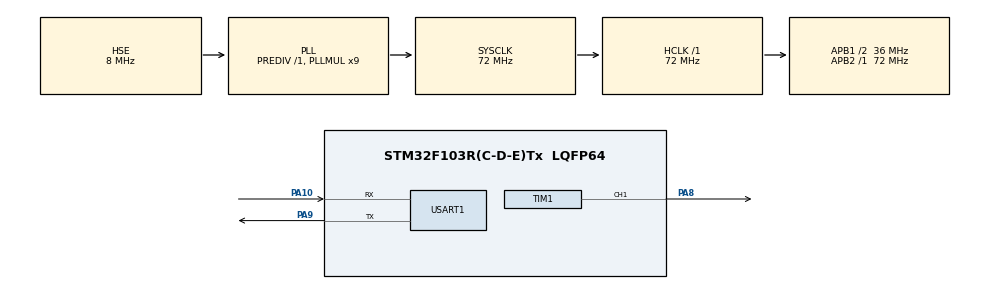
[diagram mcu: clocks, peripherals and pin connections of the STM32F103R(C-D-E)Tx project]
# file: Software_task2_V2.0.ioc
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Dma.Request0=USART1_RX
Dma.Request1=USART1_TX
Dma.USART1_RX.0.Direction=DMA_PERIPH_TO_MEMORY
Dma.USART1_RX.0.Instance=DMA1_Channel5
Dma.USART1_RX.0.MemDataAlignment=DMA_MDATAALIGN_BYTE
Dma.USART1_RX.0.MemInc=DMA_MINC_ENABLE
Dma.USART1_RX.0.Mode=DMA_NORMAL
Dma.USART1_RX.0.PeriphDataAlignment=DMA_PDATAALIGN_BYTE
Dma.USART1_RX.0.PeriphInc=DMA_PINC_DISABLE
Dma.USART1_RX.0.Priority=DMA_PRIORITY_LOW
Dma.USART1_TX.1.Direction=DMA_MEMORY_TO_PERIPH
Dma.USART1_TX.1.Instance=DMA1_Channel4
Dma.USART1_TX.1.MemDataAlignment=DMA_MDATAALIGN_BYTE
Dma.USART1_TX.1.MemInc=DMA_MINC_ENABLE
Dma.USART1_TX.1.Mode=DMA_NORMAL
Dma.USART1_TX.1.PeriphDataAlignment=DMA_PDATAALIGN_BYTE
Dma.USART1_TX.1.PeriphInc=DMA_PINC_DISABLE
Dma.USART1_TX.1.Priority=DMA_PRIORITY_LOW
FREERTOS.Queues01=Uart_Queue,1,uint16_t,0,Dynamic,NULL,NULL
FREERTOS.Tasks01=defaultTask,24,128,StartDefaultTask,Default,NULL,Dynamic,NULL,NULL;LED_Breath,9,128,LED_BreathTask,Default,NULL,Dynamic,NULL,NULL;Uart_Receive,10,128,Uart_ReceiveTask,Default,NULL,Dynamic,NULL,NULL
Mcu.Family=STM32F1
Mcu.Name=STM32F103R(C-D-E)Tx
Mcu.Package=LQFP64
NVIC.DMA1_Channel4_IRQn=true\:0\:0\:false\:false\:true\:false\:false\:true\:true
NVIC.DMA1_Channel5_IRQn=true\:0\:0\:false\:false\:true\:false\:false\:true\:true
NVIC.PriorityGroup=NVIC_PRIORITYGROUP_4
NVIC.TIM1_BRK_IRQn=true\:5\:0\:false\:false\:true\:true\:true\:true\:true
NVIC.TIM1_UP_IRQn=true\:5\:0\:false\:false\:true\:true\:true\:true\:true
NVIC.TIM6_IRQn=true\:15\:0\:false\:false\:true\:false\:false\:true\:true
NVIC.TimeBase=TIM6_IRQn
NVIC.TimeBaseIP=TIM6
NVIC.USART1_IRQn=true\:5\:0\:false\:false\:true\:true\:true\:true\:true
PA10.Mode=Asynchronous
PA10.Signal=USART1_RX
PA8.Signal=S_TIM1_CH1
PA9.Mode=Asynchronous
PA9.Signal=USART1_TX
PD0-OSC_IN.Mode=HSE-External-Oscillator
PD0-OSC_IN.Signal=RCC_OSC_IN
PD1-OSC_OUT.Mode=HSE-External-Oscillator
PD1-OSC_OUT.Signal=RCC_OSC_OUT
ProjectManager.HeapSize=0x200
ProjectManager.StackSize=0x400
ProjectManager.TargetToolchain=MDK-ARM V5.32
RCC.AHBFreq_Value=72000000
RCC.APB1CLKDivider=RCC_HCLK_DIV2
RCC.APB1Freq_Value=36000000
RCC.APB1TimFreq_Value=72000000
RCC.APB2Freq_Value=72000000
RCC.APB2TimFreq_Value=72000000
RCC.HCLKFreq_Value=72000000
RCC.PLLMUL=RCC_PLL_MUL9
RCC.PLLSourceVirtual=RCC_PLLSOURCE_HSE
RCC.SYSCLKFreq_VALUE=72000000
RCC.SYSCLKSource=RCC_SYSCLKSOURCE_PLLCLK
RCC.USBFreq_Value=72000000
SH.S_TIM1_CH1.0=TIM1_CH1,PWM Generation1 CH1
TIM1.Channel-PWM\ Generation1\ CH1=TIM_CHANNEL_1
TIM1.OCPolarity_1=TIM_OCPOLARITY_LOW
TIM1.Period=499
TIM1.Prescaler=71
USART1.VirtualMode=VM_ASYNC
VP_FREERTOS_VS_CMSIS_V2.Mode=CMSIS_V2
VP_SYS_VS_ND.Mode=No_Debug
VP_SYS_VS_tim6.Mode=TIM6
VP_TIM1_VS_ClockSourceINT.Mode=Internal
board=custom

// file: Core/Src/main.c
/* USER CODE BEGIN Header */
/**
  ******************************************************************************
  * @file           : main.c
  * @brief          : Main program body
  ******************************************************************************
  * @attention
  *
  * Copyright (c) 2023 STMicroelectronics.
  * All rights reserved.
  *
  * This software is licensed under terms that can be found in the LICENSE file
  * in the root directory of this software component.
  * If no LICENSE file comes with this software, it is provided AS-IS.
  *
  ******************************************************************************
  */
/* USER CODE END Header */
#include "main.h"
#include "cmsis_os.h"
#include "dma.h"
#include "tim.h"
#include "usart.h"
#include "gpio.h"

/* USER CODE BEGIN PD */
#define BUFFSIZE	50
char rxBUFF[BUFFSIZE]={0};
/* USER CODE END PD */

/* USER CODE BEGIN PV */
	int pwmval=0;	//PWMռ�ձ�
	int task1_flag=0;
	int task2_flag=0;
	int IRQ_flag=0;
	int Callback_flag=0;
/* USER CODE END PV */

void SystemClock_Config(void);
void MX_FREERTOS_Init(void);

int main(void)
{

  /* MCU Configuration--------------------------------------------------------*/

  /* Reset of all peripherals, Initializes the Flash interface and the Systick. */
  HAL_Init();

  /* Configure the system clock */
  SystemClock_Config();

  /* Initialize all configured peripherals */
  MX_GPIO_Init();
  MX_DMA_Init();
  MX_USART1_UART_Init();
  MX_TIM1_Init();
  /* USER CODE BEGIN 2 */
	HAL_TIM_PWM_Start(&htim1,TIM_CHANNEL_1);
//	HAL_UART_Receive_DMA(&huart1,(u8 *)rxBUFF,BUFFSIZE);
	HAL_UART_Receive_IT(&huart1, (u8 *)rxBUFF,BUFFSIZE);
  /* USER CODE END 2 */

  /* Init scheduler */
  osKernelInitialize();  /* Call init function for freertos objects (in freertos.c) */
  MX_FREERTOS_Init();

  /* Start scheduler */
  osKernelStart();
  /* We should never get here as control is now taken by the scheduler */
  /* Infinite loop */
  while (1)
  {

  }
}

void SystemClock_Config(void)
{
  RCC_OscInitTypeDef RCC_OscInitStruct = {0};
  RCC_ClkInitTypeDef RCC_ClkInitStruct = {0};

  /** Initializes the RCC Oscillators according to the specified parameters
  * in the RCC_OscInitTypeDef structure.
  */
  RCC_OscInitStruct.OscillatorType = RCC_OSCILLATORTYPE_HSE;
  RCC_OscInitStruct.HSEState = RCC_HSE_ON;
  RCC_OscInitStruct.HSEPredivValue = RCC_HSE_PREDIV_DIV1;
  RCC_OscInitStruct.HSIState = RCC_HSI_ON;
  RCC_OscInitStruct.PLL.PLLState = RCC_PLL_ON;
  RCC_OscInitStruct.PLL.PLLSource = RCC_PLLSOURCE_HSE;
  RCC_OscInitStruct.PLL.PLLMUL = RCC_PLL_MUL9;
  if (HAL_RCC_OscConfig(&RCC_OscInitStruct) != HAL_OK)
  {
    Error_Handler();
  }

  /** Initializes the CPU, AHB and APB buses clocks
  */
  RCC_ClkInitStruct.ClockType = RCC_CLOCKTYPE_HCLK|RCC_CLOCKTYPE_SYSCLK
                              |RCC_CLOCKTYPE_PCLK1|RCC_CLOCKTYPE_PCLK2;
  RCC_ClkInitStruct.SYSCLKSource = RCC_SYSCLKSOURCE_PLLCLK;
  RCC_ClkInitStruct.AHBCLKDivider = RCC_SYSCLK_DIV1;
  RCC_ClkInitStruct.APB1CLKDivider = RCC_HCLK_DIV2;
  RCC_ClkInitStruct.APB2CLKDivider = RCC_HCLK_DIV1;

  if (HAL_RCC_ClockConfig(&RCC_ClkInitStruct, FLASH_LATENCY_2) != HAL_OK)
  {
    Error_Handler();
  }
}

void HAL_TIM_PeriodElapsedCallback(TIM_HandleTypeDef *htim)
{
  if (htim->Instance == TIM6) {
    HAL_IncTick();
  }
}

void Error_Handler(void)
{
  __disable_irq();
  while (1)
  {
  }
}

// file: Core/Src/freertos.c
/* USER CODE BEGIN Header */
/**
  ******************************************************************************
  * File Name          : freertos.c
  * Description        : Code for freertos applications
  ******************************************************************************
  * @attention
  *
  * Copyright (c) 2023 STMicroelectronics.
  * All rights reserved.
  *
  * This software is licensed under terms that can be found in the LICENSE file
  * in the root directory of this software component.
  * If no LICENSE file comes with this software, it is provided AS-IS.
  *
  ******************************************************************************
  */
/* USER CODE END Header */

#include "FreeRTOS.h"
#include "task.h"
#include "main.h"
#include "cmsis_os.h"

/* USER CODE BEGIN Includes */
#include "tim.h"
#include "queue.h"
#include "usart.h"
#include "stdio.h"
/* USER CODE END Includes */

/* USER CODE BEGIN Variables */
	extern int pwmval;
	extern int task1_flag;
	extern int task2_flag;
	extern int IRQ_flag;
	extern int Callback_flag;
	extern char rxBUFF[];
	uint32_t rx_counter = 0;
	int rx_complete = 0;
/* USER CODE END Variables */
/* Definitions for defaultTask */
osThreadId_t defaultTaskHandle;
const osThreadAttr_t defaultTask_attributes = {
  .name = "defaultTask",
  .stack_size = 128 * 4,
  .priority = (osPriority_t) osPriorityNormal,
};
/* Definitions for LED_Breath */
osThreadId_t LED_BreathHandle;
const osThreadAttr_t LED_Breath_attributes = {
  .name = "LED_Breath",
  .stack_size = 128 * 4,
  .priority = (osPriority_t) osPriorityLow1,
};
/* Definitions for Uart_Receive */
osThreadId_t Uart_ReceiveHandle;
const osThreadAttr_t Uart_Receive_attributes = {
  .name = "Uart_Receive",
  .stack_size = 128 * 4,
  .priority = (osPriority_t) osPriorityLow2,
};
/* Definitions for Uart_Queue */
osMessageQueueId_t Uart_QueueHandle;
const osMessageQueueAttr_t Uart_Queue_attributes = {
  .name = "Uart_Queue"
};

/* USER CODE BEGIN FunctionPrototypes */
void DMA_TransferCompleteCallback(DMA_HandleTypeDef *hdma);
/* USER CODE END FunctionPrototypes */

void StartDefaultTask(void *argument);
void LED_BreathTask(void *argument);
void Uart_ReceiveTask(void *argument);

void MX_FREERTOS_Init(void); /* (MISRA C 2004 rule 8.1) */

void MX_FREERTOS_Init(void) {
  /* USER CODE BEGIN Init */
	HAL_DMA_RegisterCallback(&hdma_usart1_rx, HAL_DMA_XFER_CPLT_CB_ID, DMA_TransferCompleteCallback);
  /* USER CODE END Init */

  /* Create the queue(s) */
  /* creation of Uart_Queue */
  Uart_QueueHandle = osMessageQueueNew (1, sizeof(uint16_t), &Uart_Queue_attributes);

  /* Create the thread(s) */
  /* creation of defaultTask */
  defaultTaskHandle = osThreadNew(StartDefaultTask, NULL, &defaultTask_attributes);

  /* creation of LED_Breath */
  LED_BreathHandle = osThreadNew(LED_BreathTask, NULL, &LED_Breath_attributes);

  /* creation of Uart_Receive */
  Uart_ReceiveHandle = osThreadNew(Uart_ReceiveTask, NULL, &Uart_Receive_attributes);

}

void StartDefaultTask(void *argument)
{
  /* USER CODE BEGIN StartDefaultTask */
  /* Infinite loop */
  while(1)
	{
//		task3_flag++;
		osDelay(100);
	}
  /* USER CODE END StartDefaultTask */
}

void LED_BreathTask(void *argument)
{
  /* USER CODE BEGIN LED_BreathTask */
  /* Infinite loop */
  while(1)
  {
	  task1_flag++;
		  while(pwmval<500)
	  {
		  pwmval++;
		  __HAL_TIM_SetCompare(&htim1,TIM_CHANNEL_1,pwmval);
		  osDelay(5);
	  }
	  while(pwmval)
	  {
		  pwmval--;
		  __HAL_TIM_SetCompare(&htim1,TIM_CHANNEL_1,pwmval);
		  osDelay(5);
	  }
  }
  /* USER CODE END LED_BreathTask */
}

void Uart_ReceiveTask(void *argument)
{
  /* USER CODE BEGIN Uart_ReceiveTask */
  /* Infinite loop */
  // 从队列中获取数据并发送到电脑
   while(1)
   {
	   uint8_t rxData[100];
		task2_flag++;
		if (xQueueReceive(Uart_QueueHandle, &rxData, portMAX_DELAY) == pdTRUE)
		{
		  // 发送数据到电脑
		  HAL_UART_Transmit(&huart1, rxData, 100, HAL_MAX_DELAY);
		}
   }

  /* USER CODE END Uart_ReceiveTask */
}

/* USER CODE BEGIN Application */
//void HAL_UART_IdleCpltCallback(UART_HandleTypeDef *huart)
//{
//    Callback_flag=10;
//	extern char rxBUFF[];
//	printf("%s\r\n",rxBUFF);
//    if(huart->Instance==USART1)
//	{
//		if (__HAL_DMA_GET_COUNTER(huart->hdmarx) == 0)
//		{
//			uint32_t DMA_BUFFER_SIZE = 100 - huart->hdmarx->Instance->CNDTR;
//		  // 判断是否接收到回车符
//		  if (rxBUFF[DMA_BUFFER_SIZE - 1] == '\n')
//		  {
//			// 将接收到的数据通过队列传输到任务
//			  xQueueSend(Uart_QueueHandle, &rxBUFF, portMAX_DELAY);
//				Callback_flag=20;
//		  }
//		}
//	}
//}

void DMA_TransferCompleteCallback(DMA_HandleTypeDef *hdma)
{
	Callback_flag=10;
	if(hdma == &hdma_usart1_rx)
  {
    /* Get the length of the received data */
    uint16_t length = 100- __HAL_DMA_GET_COUNTER(&hdma_usart1_rx);

    /* Process the received data */
    // Send data to the computer or do other operations
    xQueueSend(Uart_QueueHandle, &rxBUFF, portMAX_DELAY);
    /* Restart the DMA reception */
    HAL_UART_Receive_DMA(&huart1,(u8*)rxBUFF, 100);

  }
}
/* USER CODE END Application */
